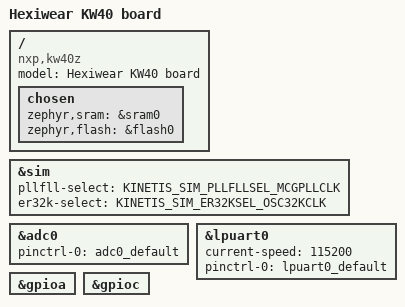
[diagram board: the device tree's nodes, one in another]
/* SPDX-License-Identifier: Apache-2.0 */

/dts-v1/;

#include <nxp/nxp_kw40z.dtsi>
#include "hexiwear_mkw40z4-pinctrl.dtsi"

/ {
	compatible = "nxp,kw40z", "nxp,mkw40z4";
	model = "Hexiwear KW40 board";

	chosen {
		zephyr,sram = &sram0;
		zephyr,flash = &flash0;
	};
};

&sim {
	pllfll-select = <KINETIS_SIM_PLLFLLSEL_MCGPLLCLK>;
	er32k-select = <KINETIS_SIM_ER32KSEL_OSC32KCLK>;
};

&adc0 {
	pinctrl-0 = <&adc0_default>;
	pinctrl-names = "default";
	status = "okay";
};

&lpuart0 {
	current-speed = <115200>;
	pinctrl-0 = <&lpuart0_default>;
	pinctrl-names = "default";
	status = "okay";
};

&gpioa {
	status = "okay";
};

&gpioc {
	status = "okay";
};
